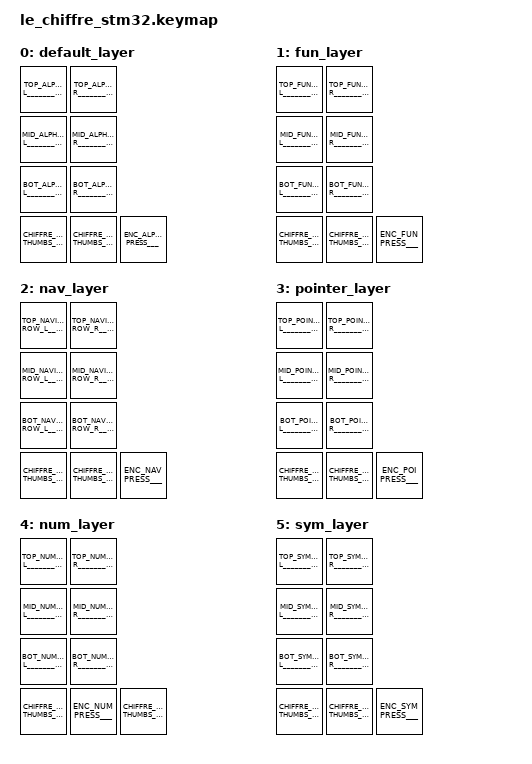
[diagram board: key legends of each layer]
/*
 * Copyright (c) 2020 The ZMK Contributors
 *
 * SPDX-License-Identifier: MIT
 */

#include <behaviors.dtsi>
#include <dt-bindings/zmk/keys.h>
#include <dt-bindings/zmk/bt.h>
#include <dt-bindings/zmk/pointing.h>
#include "shared/keymap-3x5.h"
#include "shared/behaviors.dtsi"

/ {
    chosen {
        zmk,matrix_transform = &transform_with_encoder;
    };
};

&encoder {
    status = "okay";
};

&sensors {
    status = "okay";
    triggers-per-rotation = <9>;
};

// Using layer taps on thumbs, having quick tap as well helps w/ repeating space/backspace
&lt { quick_tap_ms = <200>; };

/ {
    keymap {
        compatible = "zmk,keymap";

        default_layer {
            display-name = LABEL_ALPHAS;
            bindings = <
                _____________TOP_ALPHAS_ROW_L______________ _____________TOP_ALPHAS_ROW_R______________
                _____________MID_ALPHAS_ROW_L______________ _____________MID_ALPHAS_ROW_R______________
                _____________BOT_ALPHAS_ROW_L______________ _____________BOT_ALPHAS_ROW_R______________
                ___CHIFFRE_ALPHAS_THUMBS_L____ ___CHIFFRE_ALPHAS_THUMBS_R____    ___ENC_ALPHAS_PRESS___
            >;
            sensor-bindings = <&inc_dec_kp ___ENC_ALPHAS_INC_DEC___>;
        };

        fun_layer {
            display-name = LABEL_FUN;
            bindings = <
                _____________TOP_FUNCTION_ROW_L____________ _____________TOP_FUNCTION_ROW_R____________
                _____________MID_FUNCTION_ROW_L____________ _____________MID_FUNCTION_ROW_R____________
                _____________BOT_FUNCTION_ROW_L____________ _____________BOT_FUNCTION_ROW_R____________
                ___CHIFFRE_FUN_THUMBS_L____ ___CHIFFRE_FUN_THUMBS_R____             ___ENC_FUN_PRESS___
            >;
            sensor-bindings = <&inc_dec_kp ___ENC_FUN_INC_DEC___>;
        };

        nav_layer {
            display-name = LABEL_NAV;
            bindings = <
                ___________TOP_NAVIGATION_ROW_L____________ ___________TOP_NAVIGATION_ROW_R____________
                ___________MID_NAVIGATION_ROW_L____________ ___________MID_NAVIGATION_ROW_R____________
                ___________BOT_NAVIGATION_ROW_L____________ ___________BOT_NAVIGATION_ROW_R____________
                ___CHIFFRE_NAV_THUMBS_L____ ___CHIFFRE_NAV_THUMBS_R____             ___ENC_NAV_PRESS___
            >;
            sensor-bindings = <&inc_dec_kp ___ENC_NAV_INC_DEC___>;
        };

        pointer_layer {
            display-name = LABEL_POI;
            bindings = <
                _____________TOP_POINTER_ROW_L_____________ _____________TOP_POINTER_ROW_R_____________
                _____________MID_POINTER_ROW_L_____________ _____________MID_POINTER_ROW_R_____________
                _____________BOT_POINTER_ROW_L_____________ _____________BOT_POINTER_ROW_R_____________
                ___CHIFFRE_POI_THUMBS_L____ ___CHIFFRE_POI_THUMBS_R____             ___ENC_POI_PRESS___
            >;
            sensor-bindings = <&inc_dec_kp ___ENC_POI_INC_DEC___>;
        };

        num_layer {
            display-name = LABEL_NUM;
            bindings = <
                _____________TOP_NUMERAL_ROW_L_____________ _____________TOP_NUMERAL_ROW_R_____________
                _____________MID_NUMERAL_ROW_L_____________ _____________MID_NUMERAL_ROW_R_____________
                _____________BOT_NUMERAL_ROW_L_____________ _____________BOT_NUMERAL_ROW_R_____________
                ___CHIFFRE_NUM_THUMBS_L____        ___ENC_NUM_PRESS___      ___CHIFFRE_NUM_THUMBS_R____
            >;
            sensor-bindings = <&inc_dec_kp ___ENC_NUM_INC_DEC___>;
        };

        sym_layer {
            display-name = LABEL_SYM;
            bindings = <
                _____________TOP_SYMBOLS_ROW_L_____________ _____________TOP_SYMBOLS_ROW_R_____________
                _____________MID_SYMBOLS_ROW_L_____________ _____________MID_SYMBOLS_ROW_R_____________
                _____________BOT_SYMBOLS_ROW_L_____________ _____________BOT_SYMBOLS_ROW_R_____________
                ___CHIFFRE_SYM_THUMBS_L____ ___CHIFFRE_SYM_THUMBS_R____             ___ENC_SYM_PRESS___
            >;
            sensor-bindings = <&inc_dec_kp ___ENC_SYM_INC_DEC___>;
        };
    };
};
